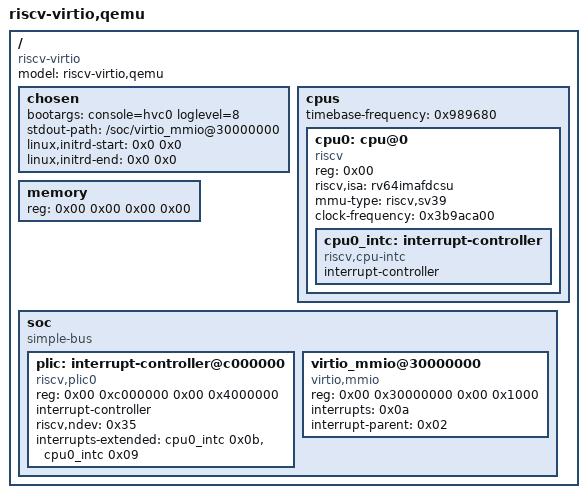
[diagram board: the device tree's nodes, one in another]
/dts-v1/;

/ {
    #address-cells = <0x02>;
    #size-cells = <0x02>;
    compatible = "riscv-virtio";
    model = "riscv-virtio,qemu";

    chosen {
		bootargs = "console=hvc0 loglevel=8";
        stdout-path = "/soc/virtio_mmio@30000000";
        //stdout-path = "/soc/uart@10000000";
		linux,initrd-start = <0x0 0x0>;
        linux,initrd-end = <0x0 0x0>;
    };

    cpus {
        #address-cells = <0x01>;
        #size-cells = <0x00>;
        timebase-frequency = <0x989680>;

        cpu0: cpu@0 {
            device_type = "cpu";
            reg = <0x00>;
            status = "okay";
            compatible = "riscv";
            riscv,isa = "rv64imafdcsu";
            mmu-type = "riscv,sv39";
            clock-frequency = <0x3b9aca00>;

            cpu0_intc: interrupt-controller {
                #interrupt-cells = <0x01>;
                interrupt-controller;
                compatible = "riscv,cpu-intc";
                phandle = <0x01>;
            };
        };
    };

    memory {
        device_type = "memory";
        reg = <0x00 0x00 0x00 0x00>;
    };

    soc {
        #address-cells = <0x02>;
        #size-cells = <0x02>;
        compatible = "simple-bus";
        ranges;

        plic: interrupt-controller@c000000 {
            compatible = "riscv,plic0";
            reg = <0x00 0xc000000 0x00 0x4000000>;
            interrupt-controller;
            #interrupt-cells = <0x01>;
            riscv,ndev = <0x35>;
            interrupts-extended = <&cpu0_intc 0x0b &cpu0_intc 0x09>;
            phandle = <0x02>; 
        };

        //uart@10000000 {
        //    compatible = "ns16550a";
        //    reg = <0x00 0x10000000 0x00 0x100>;
        //    interrupts = <0x0a>;
        //    interrupt-parent = <0x02>;
        //    clock-frequency = <3686400>; 
        //};

        virtio_mmio@30000000 {
            compatible = "virtio,mmio";
            reg = <0x00 0x30000000 0x00 0x1000>;
			interrupts = <0x0a>;
            interrupt-parent = <0x02>;
        };
    };
};
